# ESP32-H21 register map
Vendor: ESPRESSIF SYSTEMS (SHANGHAI) CO., LTD.; Series: ESP32 H-Series; File version: 1
CPU: RV32IMAC r0p0, little endian, no MPU, no FPU, 0 interrupt priority bits
Address unit: 32 bits
Registers are 32-bit, read-write, reset 0x0 unless marked. A register's access mark holds for its fields unless they carry their own. Offsets are from the block's base; [hi:lo] are bit positions; {n}, {i} and the like mark numbered series.

## EFUSE — eFuse Controller
Base 0x600B4000
{0x0+4i} PGM_DATA{i} (i=0..7) — Represents pgm_data{i}
  [31:0] PGM_DATA — Configures the %sth 32-bit data to be programmed.
{0x20+4i} PGM_CHECK_VALUE{i} (i=0..2) — Represents pgm_check_value{i}
  [31:0] PGM_RS_DATA — Configures the %sth RS code to be programmed.
0x2C RD_WR_DIS ro — Represents rd_wr_dis
  [31:0] WR_DIS — Represents whether programming of individual eFuse memory bit is disabled or enabled.\\ 1: Disabled\\ 0: Enabled\\
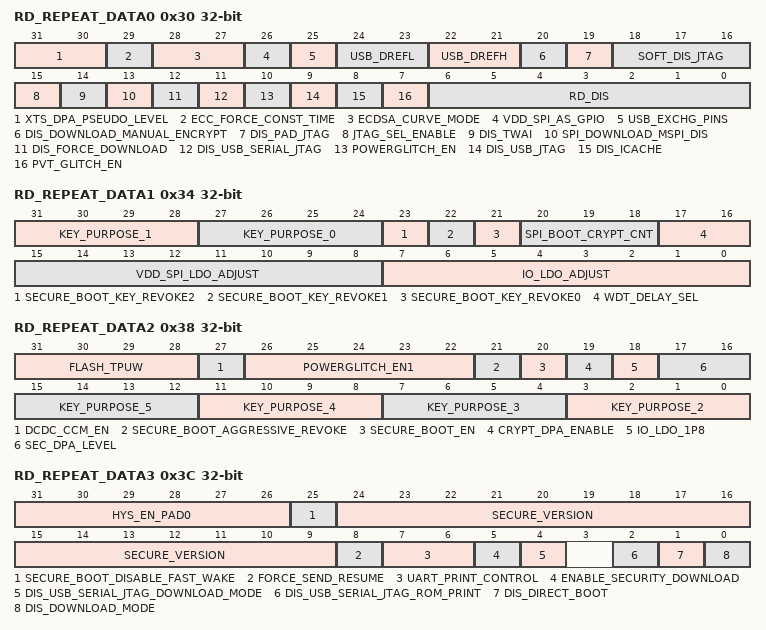
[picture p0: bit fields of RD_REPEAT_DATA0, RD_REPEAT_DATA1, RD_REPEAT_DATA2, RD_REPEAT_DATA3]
0x30 RD_REPEAT_DATA0 ro — Represents rd_repeat_data
  [31:30] XTS_DPA_PSEUDO_LEVEL — Represents control method of xts pseudo-round anti-dpa attack function.\\ 0: Controlled by register\\ 1-3: The higher the value is, the more pseudo-rounds are inserted to the xts-aes calculation.\\
  [29] ECC_FORCE_CONST_TIME — Represents whether to permanently turn on ECC const-time mode.\\ 0: Disabled\\ 1: Enabled\\
  [28:27] ECDSA_CURVE_MODE — Represents the configuration of the curve of ECDSA calculation.\\ 0: Only enable P256\\ 1: Only enable P192\\ 2: Both enable P256 and P192\\ 3: Only enable P256\\
  [26] VDD_SPI_AS_GPIO — Represents whether vdd spi pin is functioned as gpio.\\ 1: Functioned\\ 0: Not functioned\\
  [25] USB_EXCHG_PINS — Represents whether the D+ and D- pins is exchanged.\\ 1: Exchanged\\ 0: Not exchanged\\
  [24:23] USB_DREFL — Represents single-end input threshold vrefl, 0.8 V to 1.04 V with step of 80 mV, stored in eFuse.\\
  [22:21] USB_DREFH — Represents single-end input threshold vrefh, 1.76 V to 2 V with step of 80 mV, stored in eFuse.\\
  [20] DIS_DOWNLOAD_MANUAL_ENCRYPT — Represents whether flash encryption is disabled (except in SPI boot mode).\\ 1: Disabled\\ 0: Enabled\\
  [19] DIS_PAD_JTAG — Represents whether PAD JTAG is disabled in the hard way (permanently).\\ 1: Disabled\\ 0: Enabled\\
  [18:16] SOFT_DIS_JTAG — Represents whether PAD JTAG is disabled in the soft way. It can be restarted via HMAC. \\ Odd count of bits with a value of 1: Disabled\\ Even count of bits with a value of 1: Enabled\\
  [15] JTAG_SEL_ENABLE — Represents whether the selection of a JTAG signal source through the strapping pin value is enabled when both EFUSE_DIS_PAD_JTAG and EFUSE_DIS_USB_JTAG are configured to 0. For more information, please refer to Chapter Placeholder.\\ 1: Enabled\\ 0: Disabled\\
  [14] DIS_TWAI — Represents whether TWAI function is disabled. \\ 1: Disabled\\ 0: Enabled\\
  [13] SPI_DOWNLOAD_MSPI_DIS — Represents accessing MSPI flash/MSPI RAM by SYS AXI matrix is disabled during boot_mode_download.\\ 1: Disabled\\ 0: Enabled\\
  [12] DIS_FORCE_DOWNLOAD — Represents whether the function that forces chip into Download mode is disabled. \\ 1: Disabled\\ 0: Enabled\\
  [11] DIS_USB_SERIAL_JTAG — Represents whether to disable USB-Serial-JTAG.\\
  [10] POWERGLITCH_EN — Represents whether to enable power glitch function.\\
  [9] DIS_USB_JTAG — Represents whether the USB-to-JTAG function in USB Serial/JTAG is disabled. \\ 1: Disabled\\ 0: Enabled\\
  [8] DIS_ICACHE — Represents whether icache is disabled or enabled.\\ 1: Disabled\\ 0: Enabled\\
  [7] PVT_GLITCH_EN — Represents whether to enable PVT power glitch monitor function.\\1: Enable. \\0: Disable\\
  [6:0] RD_DIS — Represents whether reading of individual eFuse block(block4~block10) is disabled or enabled.\\ 1: Disabled\\ 0: Enabled\\
0x34 RD_REPEAT_DATA1 ro — Represents rd_repeat_data
  [31:28] KEY_PURPOSE_1 — Represents the purpose of Key1. See Table tab:efuse-key-purpose.\\
  [27:24] KEY_PURPOSE_0 — Represents the purpose of Key0. See Table tab:efuse-key-purpose.\\
  [23] SECURE_BOOT_KEY_REVOKE2 — Represents whether revoking Secure Boot key 2 is enabled. \\ 1: Enabled\\ 0: Disabled\\
  [22] SECURE_BOOT_KEY_REVOKE1 — Represents whether revoking Secure Boot key 1 is enabled. \\ 1: Enabled\\ 0: Disabled\\
  [21] SECURE_BOOT_KEY_REVOKE0 — Represents whether revoking Secure Boot key 0 is enabled. \\ 1: Enabled\\ 0: Disabled\\
  [20:18] SPI_BOOT_CRYPT_CNT — Represents whether SPI boot encryption/decryption is enabled. \\ Odd count of bits with a value of 1: Enabled\\ Even count of bits with a value of 1: Disabled\\
  [17:16] WDT_DELAY_SEL — Represents RTC watchdog timeout threshold.\\ 0：The originally configured STG0 threshold × 2\\ 1：The originally configured STG0 threshold × 4\\ 2：The originally configured STG0 threshold × 8\\ 3：The originally configured STG0 threshold × 16\\
  [15:8] VDD_SPI_LDO_ADJUST — Represents configuration of FLASH LDO mode and voltage.\\
  [7:0] IO_LDO_ADJUST — Represents configuration of IO LDO mode and voltage.\\
0x38 RD_REPEAT_DATA2 ro — Represents rd_repeat_data
  [31:28] FLASH_TPUW — Represents the flash waiting time after power-up. Measurement unit: ms.\\ When the value is less than 15, the waiting time is the programmed value. Otherwise, the waiting time is a fixed value, i.e. 30 ms.\\
  [27] DCDC_CCM_EN — Represents whether change DCDC to CCM mode.
  [26:22] POWERGLITCH_EN1 — Represents whether to enable power glitch function when chip power on.\\
  [21] SECURE_BOOT_AGGRESSIVE_REVOKE — Represents whether aggressive revocation of Secure Boot is enabled.\\ 1: Enabled\\ 0: Disabled\\
  [20] SECURE_BOOT_EN — Represents whether Secure Boot is enabled.\\ 1: Enabled\\ 0: Disabled\\
  [19] CRYPT_DPA_ENABLE — Represents whether defense against DPA attack is enabled.\\ 1: Enabled\\ 0: Disabled\\
  [18] IO_LDO_1P8 — Represents select IO LDO voltage to 1.8V or 3.3V.\\ 1: 1.8V\\ 0: 3.3V\\
  [17:16] SEC_DPA_LEVEL — Represents the security level of anti-DPA attack. The level is adjusted by configuring the clock random frequency division mode.\\ 0: Security level is SEC_DPA_OFF\\ 1: Security level is SEC_DPA_LOW\\ 2: Security level is SEC_DPA_MIDDLE\\ 3: Security level is SEC_DPA_HIGH\\ For more information, please refer to Chapter mod:sysreg > Section sec:sysreg-anti-dpa-attack-security-control.\\
  [4n-5:4n-8] KEY_PURPOSE_{n} (n=2..5) — Represents the purpose of Key{n}. See Table tab:efuse-key-purpose.\\
0x3C RD_REPEAT_DATA3 ro — Represents rd_repeat_data
  [31:26] HYS_EN_PAD0 — Represents whether to enable the hysteresis function of pad 0-5.\\ 0: Disabled\\ 1: Enabled\\
  [25] SECURE_BOOT_DISABLE_FAST_WAKE — Represents whether FAST VERIFY ON WAKE is disabled when Secure Boot is enabled.\\ 1: Disabled\\ 0: Enabled\\
  [24:9] SECURE_VERSION — Represents the security version used by ESP-IDF anti-rollback feature.\\
  [8] FORCE_SEND_RESUME — Represents whether ROM code is forced to send a resume command during SPI boot.\\ 1: Forced\\ 0: Not forced\\
  [7:6] UART_PRINT_CONTROL — Represents the type of UART printing.\\ 0: Force enable printing.\\ 1: Enable printing when GPIO8 is reset at low level.\\ 2: Enable printing when GPIO8 is reset at high level.\\ 3: Force disable printing.\\
  [5] ENABLE_SECURITY_DOWNLOAD — Represents whether security download is enabled. Only UART is supported for download. Reading/writing RAM or registers is not supported (i.e. Stub download is not supported).\\ 1: Enabled\\ 0: Disabled\\
  [4] DIS_USB_SERIAL_JTAG_DOWNLOAD_MODE — Represents whether the USB-Serial-JTAG download function is disabled.\\ 1: Disabled\\ 0: Enabled\\
  [2] DIS_USB_SERIAL_JTAG_ROM_PRINT — Represents whether print from USB-Serial-JTAG during ROM boot is disabled.\\ 1: Disabled\\ 0: Enabled\\
  [1] DIS_DIRECT_BOOT — Represents whether direct boot mode is disabled.\\ 1: Disabled\\ 0: Enabled\\
  [0] DIS_DOWNLOAD_MODE — Represents whether all download modes are disabled.\\ 1: Disabled\\ 0: Enabled\\
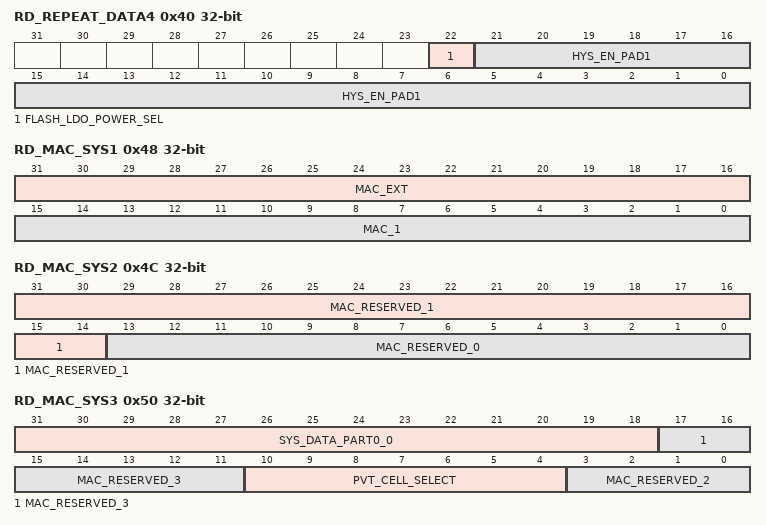
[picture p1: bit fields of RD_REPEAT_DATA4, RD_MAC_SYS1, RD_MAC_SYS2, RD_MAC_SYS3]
0x40 RD_REPEAT_DATA4 ro — Represents rd_repeat_data
  [22] FLASH_LDO_POWER_SEL — Represents which flash LDO is selected.\\ 0: FLASH LDO 1P8.\\ 1: FLASH LDO 1P2.\\
  [21:0] HYS_EN_PAD1 — Represents whether to enable the hysteresis function of pad 6-27.\\ 0: Disabled\\ 1: Enabled\\
0x44 RD_MAC_SYS0 ro — Represents rd_mac_sys
  [31:0] MAC_0 — Represents MAC address. Low 32-bit.
0x48 RD_MAC_SYS1 ro — Represents rd_mac_sys
  [31:16] MAC_EXT — Represents the extended bits of MAC address.
  [15:0] MAC_1 — Represents MAC address. High 16-bit.
0x4C RD_MAC_SYS2 ro — Represents rd_mac_sys
  [31:14] MAC_RESERVED_1 — Reserved.
  [13:0] MAC_RESERVED_0 — Reserved.
0x50 RD_MAC_SYS3 ro — Represents rd_mac_sys
  [31:18] SYS_DATA_PART0_0 — Represents the first 14-bit of zeroth part of system data.
  [17:11] MAC_RESERVED_3 — Reserved.
  [10:4] PVT_CELL_SELECT — Represents the selection of Power glitch monitor PVT cell.\\
  [3:0] MAC_RESERVED_2 — Reserved.
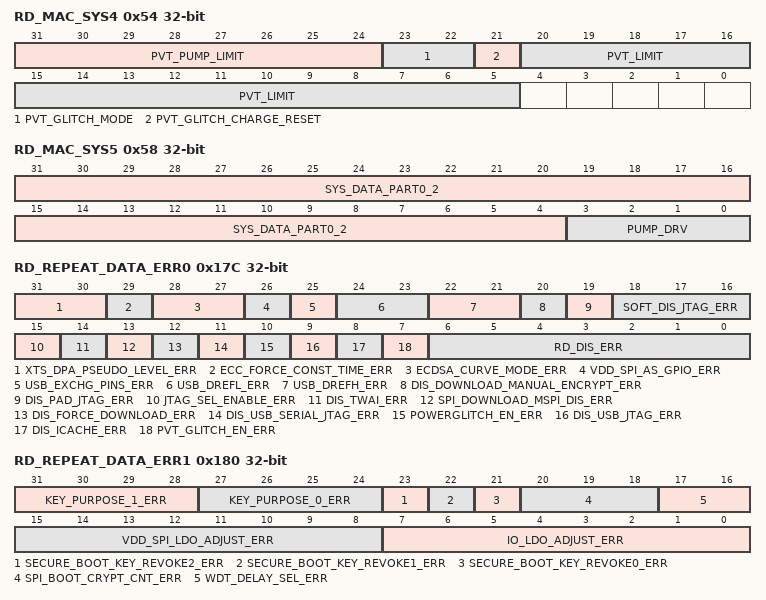
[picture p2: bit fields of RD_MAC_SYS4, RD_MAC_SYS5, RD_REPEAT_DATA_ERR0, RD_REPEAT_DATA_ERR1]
0x54 RD_MAC_SYS4 ro — Represents rd_mac_sys
  [31:24] PVT_PUMP_LIMIT — Represents the configuration voltage monitor limit for charge pump.\\
  [23:22] PVT_GLITCH_MODE — Represents the configuration of glitch mode.\\
  [21] PVT_GLITCH_CHARGE_RESET — Represents whether to trigger reset or charge pump when PVT power glitch happened.\\ 1:Trigger charge pump. \\ 0:Trigger reset\\
  [20:5] PVT_LIMIT — Represents the threshold of power glitch monitor.\\
0x58 RD_MAC_SYS5 ro — Represents rd_mac_sys
  [31:4] SYS_DATA_PART0_2 — Represents the second 28-bit of zeroth part of system data.
  [3:0] PUMP_DRV — Use to configure charge pump voltage gain.\\
{0x5C+4i} RD_SYS_PART1_DATA{i} (i=0..7) ro — Represents rd_sys_part1_data{i}
  [31:0] SYS_DATA_PART1 — Represents the zeroth 32-bit of first part of system data.
{0x7C+4i} RD_USR_DATA{i} (i=0..7) ro — Represents rd_usr_data{i}
  [31:0] USR_DATA — Represents the zeroth 32-bit of block3 (user).
{0x9C+4i} RD_KEY0_DATA{i} (i=0..7) ro — Represents rd_key0_data{i}
  [31:0] KEY0_DATA — Represents the zeroth 32-bit of key0.
{0xBC+4i} RD_KEY1_DATA{i} (i=0..7) ro — Represents rd_key1_data{i}
  [31:0] KEY1_DATA — Represents the zeroth 32-bit of key1.
{0xDC+4i} RD_KEY2_DATA{i} (i=0..7) ro — Represents rd_key2_data{i}
  [31:0] KEY2_DATA — Represents the zeroth 32-bit of key2.
{0xFC+4i} RD_KEY3_DATA{i} (i=0..7) ro — Represents rd_key3_data{i}
  [31:0] KEY3_DATA — Represents the zeroth 32-bit of key3.
{0x11C+4i} RD_KEY4_DATA{i} (i=0..7) ro — Represents rd_key4_data{i}
  [31:0] KEY4_DATA — Represents the zeroth 32-bit of key4.
{0x13C+4i} RD_KEY5_DATA{i} (i=0..7) ro — Represents rd_key5_data{i}
  [31:0] KEY5_DATA — Represents the zeroth 32-bit of key5.
{0x15C+4i} RD_SYS_PART2_DATA{i} (i=0..7) ro — Represents rd_sys_part2_data{i}
  [31:0] SYS_DATA_PART2 — Represents the zeroth 32-bit of second part of system data.
0x17C RD_REPEAT_DATA_ERR0 ro — Represents rd_repeat_data_err
  [31:30] XTS_DPA_PSEUDO_LEVEL_ERR — Represents the programming error of EFUSE_XTS_DPA_PSEUDO_LEVEL
  [29] ECC_FORCE_CONST_TIME_ERR — Represents the programming error of EFUSE_ECC_FORCE_CONST_TIME
  [28:27] ECDSA_CURVE_MODE_ERR — Represents the programming error of EFUSE_ECDSA_CURVE_MODE
  [26] VDD_SPI_AS_GPIO_ERR — Represents the programming error of EFUSE_VDD_SPI_AS_GPIO
  [25] USB_EXCHG_PINS_ERR — Represents the programming error of EFUSE_USB_EXCHG_PINS
  [24:23] USB_DREFL_ERR — Represents the programming error of EFUSE_USB_DREFL
  [22:21] USB_DREFH_ERR — Represents the programming error of EFUSE_USB_DREFH
  [20] DIS_DOWNLOAD_MANUAL_ENCRYPT_ERR — Represents the programming error of EFUSE_DIS_DOWNLOAD_MANUAL_ENCRYPT
  [19] DIS_PAD_JTAG_ERR — Represents the programming error of EFUSE_DIS_PAD_JTAG
  [18:16] SOFT_DIS_JTAG_ERR — Represents the programming error of EFUSE_SOFT_DIS_JTAG
  [15] JTAG_SEL_ENABLE_ERR — Represents the programming error of EFUSE_JTAG_SEL_ENABLE
  [14] DIS_TWAI_ERR — Represents the programming error of EFUSE_DIS_TWAI
  [13] SPI_DOWNLOAD_MSPI_DIS_ERR — Represents the programming error of EFUSE_SPI_DOWNLOAD_MSPI_DIS
  [12] DIS_FORCE_DOWNLOAD_ERR — Represents the programming error of EFUSE_DIS_FORCE_DOWNLOAD
  [11] DIS_USB_SERIAL_JTAG_ERR — Represents the programming error of EFUSE_DIS_USB_SERIAL_JTAG
  [10] POWERGLITCH_EN_ERR — Represents the programming error of EFUSE_POWERGLITCH_EN
  [9] DIS_USB_JTAG_ERR — Represents the programming error of EFUSE_DIS_USB_JTAG
  [8] DIS_ICACHE_ERR — Represents the programming error of EFUSE_DIS_ICACHE
  [7] PVT_GLITCH_EN_ERR — Represents the programming error of EFUSE_PVT_GLITCH_EN
  [6:0] RD_DIS_ERR — Represents the programming error of EFUSE_RD_DIS
0x180 RD_REPEAT_DATA_ERR1 ro — Represents rd_repeat_data_err
  [31:28] KEY_PURPOSE_1_ERR — Represents the programming error of EFUSE_KEY_PURPOSE_1
  [27:24] KEY_PURPOSE_0_ERR — Represents the programming error of EFUSE_KEY_PURPOSE_0
  [23] SECURE_BOOT_KEY_REVOKE2_ERR — Represents the programming error of EFUSE_SECURE_BOOT_KEY_REVOKE2
  [22] SECURE_BOOT_KEY_REVOKE1_ERR — Represents the programming error of EFUSE_SECURE_BOOT_KEY_REVOKE1
  [21] SECURE_BOOT_KEY_REVOKE0_ERR — Represents the programming error of EFUSE_SECURE_BOOT_KEY_REVOKE0
  [20:18] SPI_BOOT_CRYPT_CNT_ERR — Represents the programming error of EFUSE_SPI_BOOT_CRYPT_CNT
  [17:16] WDT_DELAY_SEL_ERR — Represents the programming error of EFUSE_WDT_DELAY_SEL
  [15:8] VDD_SPI_LDO_ADJUST_ERR — Represents the programming error of EFUSE_VDD_SPI_LDO_ADJUST
  [7:0] IO_LDO_ADJUST_ERR — Represents the programming error of EFUSE_IO_LDO_ADJUST
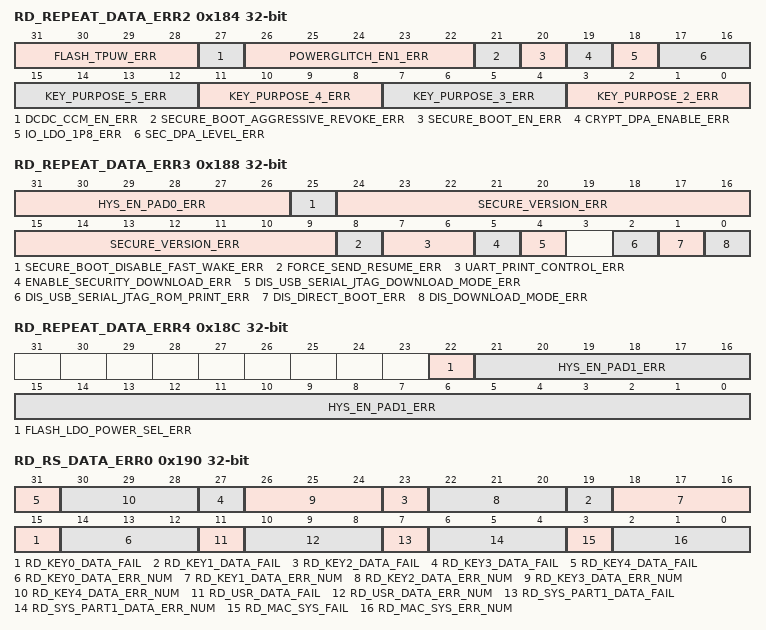
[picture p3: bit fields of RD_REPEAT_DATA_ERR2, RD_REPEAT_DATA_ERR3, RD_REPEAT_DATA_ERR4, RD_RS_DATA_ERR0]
0x184 RD_REPEAT_DATA_ERR2 ro — Represents rd_repeat_data_err
  [31:28] FLASH_TPUW_ERR — Represents the programming error of EFUSE_FLASH_TPUW
  [27] DCDC_CCM_EN_ERR — Represents the programming error of EFUSE_DCDC_CCM_EN
  [26:22] POWERGLITCH_EN1_ERR — Represents the programming error of EFUSE_POWERGLITCH_EN1
  [21] SECURE_BOOT_AGGRESSIVE_REVOKE_ERR — Represents the programming error of EFUSE_SECURE_BOOT_AGGRESSIVE_REVOKE
  [20] SECURE_BOOT_EN_ERR — Represents the programming error of EFUSE_SECURE_BOOT_EN
  [19] CRYPT_DPA_ENABLE_ERR — Represents the programming error of EFUSE_CRYPT_DPA_ENABLE
  [18] IO_LDO_1P8_ERR — Represents the programming error of EFUSE_IO_LDO_1P8
  [17:16] SEC_DPA_LEVEL_ERR — Represents the programming error of EFUSE_SEC_DPA_LEVEL
  [4n-5:4n-8] KEY_PURPOSE_{n}_ERR (n=2..5) — Represents the programming error of EFUSE_KEY_PURPOSE_{n}
0x188 RD_REPEAT_DATA_ERR3 ro — Represents rd_repeat_data_err
  [31:26] HYS_EN_PAD0_ERR — Represents the programming error of EFUSE_HYS_EN_PAD0
  [25] SECURE_BOOT_DISABLE_FAST_WAKE_ERR — Represents the programming error of EFUSE_SECURE_BOOT_DISABLE_FAST_WAKE
  [24:9] SECURE_VERSION_ERR — Represents the programming error of EFUSE_SECURE_VERSION
  [8] FORCE_SEND_RESUME_ERR — Represents the programming error of EFUSE_FORCE_SEND_RESUME
  [7:6] UART_PRINT_CONTROL_ERR — Represents the programming error of EFUSE_UART_PRINT_CONTROL
  [5] ENABLE_SECURITY_DOWNLOAD_ERR — Represents the programming error of EFUSE_ENABLE_SECURITY_DOWNLOAD
  [4] DIS_USB_SERIAL_JTAG_DOWNLOAD_MODE_ERR — Represents the programming error of EFUSE_DIS_USB_SERIAL_JTAG_DOWNLOAD_MODE
  [2] DIS_USB_SERIAL_JTAG_ROM_PRINT_ERR — Represents the programming error of EFUSE_DIS_USB_SERIAL_JTAG_ROM_PRINT
  [1] DIS_DIRECT_BOOT_ERR — Represents the programming error of EFUSE_DIS_DIRECT_BOOT
  [0] DIS_DOWNLOAD_MODE_ERR — Represents the programming error of EFUSE_DIS_DOWNLOAD_MODE
0x18C RD_REPEAT_DATA_ERR4 ro — Represents rd_repeat_data_err
  [22] FLASH_LDO_POWER_SEL_ERR — Represents the programming error of EFUSE_FLASH_LDO_POWER_SEL
  [21:0] HYS_EN_PAD1_ERR — Represents the programming error of EFUSE_HYS_EN_PAD1
0x190 RD_RS_DATA_ERR0 ro — Represents rd_rs_data_err
  [4n+15] RD_KEY{n}_DATA_FAIL (n=0..4) — Represents error status of register.\\0: Means no failure and that the data of rd_key{n}_data is reliable\\ 1: Means that programming rd_key{n}_data failed and the number of error bytes is over 6.
  [4n+14:4n+12] RD_KEY{n}_DATA_ERR_NUM (n=0..4) — Represents the error number of registers.\\The value of this signal means the number of error bytes in rd_key{n}_data
  [11] RD_USR_DATA_FAIL — Represents error status of register.\\0: Means no failure and that the data of rd_usr_data is reliable\\ 1: Means that programming rd_usr_data failed and the number of error bytes is over 6.
  [10:8] RD_USR_DATA_ERR_NUM — Represents the error number of registers.\\The value of this signal means the number of error bytes in rd_usr_data
  [7] RD_SYS_PART1_DATA_FAIL — Represents error status of register.\\0: Means no failure and that the data of rd_sys_part1_data is reliable\\ 1: Means that programming rd_sys_part1_data failed and the number of error bytes is over 6.
  [6:4] RD_SYS_PART1_DATA_ERR_NUM — Represents the error number of registers.\\The value of this signal means the number of error bytes in rd_sys_part1_data
  [3] RD_MAC_SYS_FAIL — Represents error status of register.\\0: Means no failure and that the data of rd_mac_sys is reliable\\ 1: Means that programming rd_mac_sys failed and the number of error bytes is over 6.
  [2:0] RD_MAC_SYS_ERR_NUM — Represents the error number of registers.\\The value of this signal means the number of error bytes in rd_mac_sys
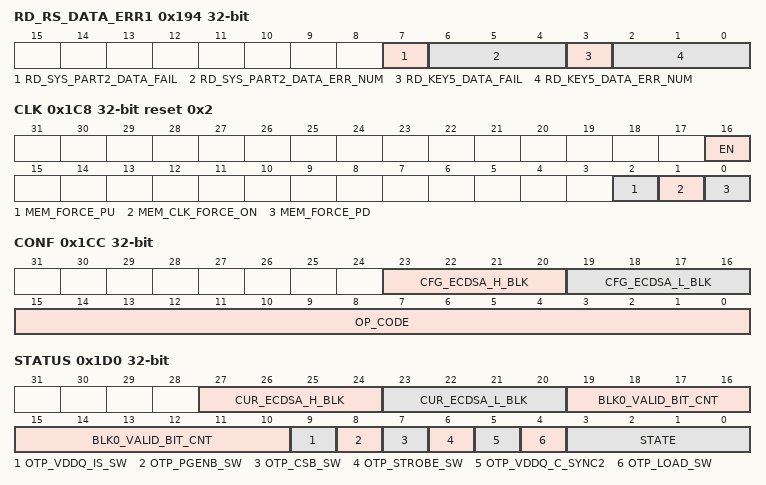
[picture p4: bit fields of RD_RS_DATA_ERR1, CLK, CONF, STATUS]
0x194 RD_RS_DATA_ERR1 ro — Represents rd_rs_data_err
  [7] RD_SYS_PART2_DATA_FAIL — Represents error status of register.\\0: Means no failure and that the data of rd_sys_part2_data is reliable\\ 1: Means that programming rd_sys_part2_data failed and the number of error bytes is over 6.
  [6:4] RD_SYS_PART2_DATA_ERR_NUM — Represents the error number of registers.\\The value of this signal means the number of error bytes in rd_sys_part2_data
  [3] RD_KEY5_DATA_FAIL — Represents error status of register.\\0: Means no failure and that the data of rd_key5_data is reliable\\ 1: Means that programming rd_key5_data failed and the number of error bytes is over 6.
  [2:0] RD_KEY5_DATA_ERR_NUM — Represents the error number of registers.\\The value of this signal means the number of error bytes in rd_key5_data
0x198 DATE reset 0x2410120 — eFuse version register.
  [27:0] DATE — Represents eFuse version. Date:2024-10-12 12:09:57, ScriptRev:892332a1019d3a17987b08c6835edce28f46e261
0x1C8 CLK reset 0x2 — eFuse clcok configuration register.
  [16] EN — Configures whether to force enable eFuse register configuration clock signal.\\ 1: Force\\ 0: The clock is enabled only during the reading and writing of registers\\
  [2] MEM_FORCE_PU — Configures whether to force power up eFuse SRAM.\\ 1: Force\\ 0: No effect\\
  [1] MEM_CLK_FORCE_ON — Configures whether to force activate clock signal of eFuse SRAM.\\ 1: Force activate\\ 0: No effect\\
  [0] MEM_FORCE_PD — Configures whether to force power down eFuse SRAM.\\ 1: Force\\ 0: No effect\\
0x1CC CONF — eFuse operation mode configuraiton register
  [23:20] CFG_ECDSA_H_BLK — Configures which block to use for ECDSA key high part output.
  [19:16] CFG_ECDSA_L_BLK — Configures which block to use for ECDSA key low part output.
  [15:0] OP_CODE — Configures operation command type.\\ 0x5A5A: Program operation command\\ 0x5AA5: Read operation command\\ Other values: No effect\\
0x1D0 STATUS ro — eFuse status register.
  [27:24] CUR_ECDSA_H_BLK — Represents which block is used for ECDSA key high part output.
  [23:20] CUR_ECDSA_L_BLK — Represents which block is used for ECDSA key low part output.
  [19:10] BLK0_VALID_BIT_CNT — Represents the number of block valid bit.
  [9] OTP_VDDQ_IS_SW — Represents the value of OTP_VDDQ_IS_SW.
  [8] OTP_PGENB_SW — Represents the value of OTP_PGENB_SW.
  [7] OTP_CSB_SW — Represents the value of OTP_CSB_SW.
  [6] OTP_STROBE_SW — Represents the value of OTP_STROBE_SW.
  [5] OTP_VDDQ_C_SYNC2 — Represents the value of OTP_VDDQ_C_SYNC2.
  [4] OTP_LOAD_SW — Represents the value of OTP_LOAD_SW.
  [3:0] STATE — Represents the state of the eFuse state machine.\\ 0: Reset state, the initial state after power-up\\ 1: Idle state\\ Other values: Non-idle state\\
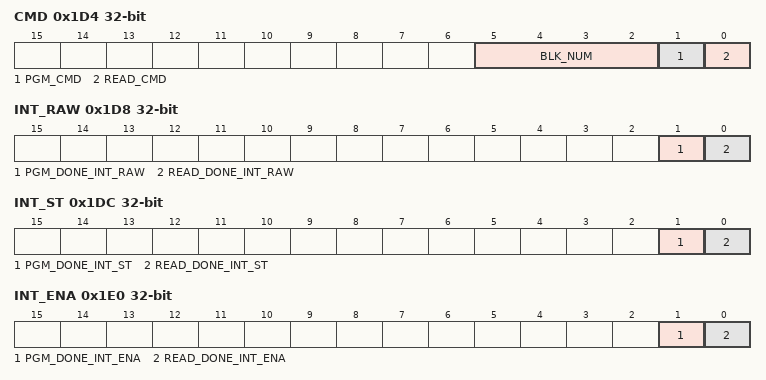
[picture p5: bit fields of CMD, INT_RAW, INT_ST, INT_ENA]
0x1D4 CMD — eFuse command register.
  [5:2] BLK_NUM — Configures the serial number of the block to be programmed. Value 0-10 corresponds to block number 0-10, respectively.
  [1] PGM_CMD — Configures whether to send programing commands.\\ 1: Send\\ 0: No effect\\
  [0] READ_CMD — Configures whether to send read commands.\\ 1: Send\\ 0: No effect\\
0x1D8 INT_RAW ro — eFuse raw interrupt register.
  [1] PGM_DONE_INT_RAW — The raw interrupt status of EFUSE_PGM_DONE_INT.
  [0] READ_DONE_INT_RAW — The raw interrupt status of EFUSE_READ_DONE_INT.
0x1DC INT_ST ro — eFuse interrupt status register.
  [1] PGM_DONE_INT_ST — The masked interrupt status of EFUSE_PGM_DONE_INT.
  [0] READ_DONE_INT_ST — The masked interrupt status of EFUSE_READ_DONE_INT.
0x1E0 INT_ENA — eFuse interrupt enable register.
  [1] PGM_DONE_INT_ENA — Write 1 to enable EFUSE_PGM_DONE_INT.
  [0] READ_DONE_INT_ENA — Write 1 to enable EFUSE_READ_DONE_INT.
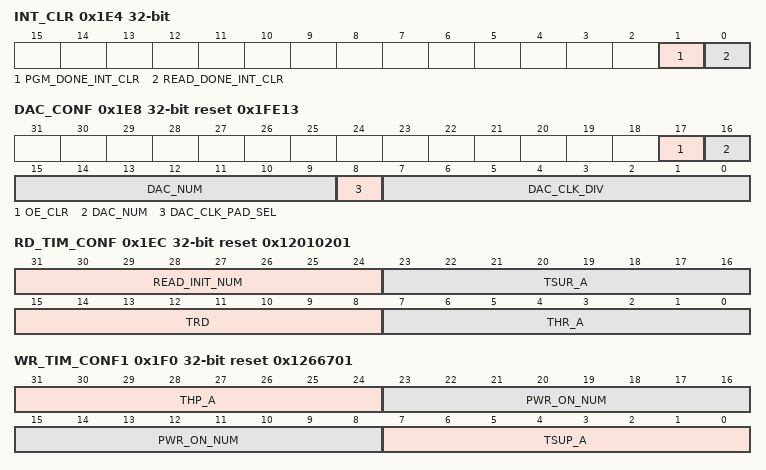
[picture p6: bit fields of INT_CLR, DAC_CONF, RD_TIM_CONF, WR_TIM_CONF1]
0x1E4 INT_CLR wo — eFuse interrupt clear register.
  [1] PGM_DONE_INT_CLR — Write 1 to clear EFUSE_PGM_DONE_INT.
  [0] READ_DONE_INT_CLR — Write 1 to clear EFUSE_READ_DONE_INT.
0x1E8 DAC_CONF reset 0x1FE13 — Controls the eFuse programming voltage.
  [17] OE_CLR — Configures whether to reduce the power supply of programming voltage.\\ 0: Not reduce\\ 1: Reduce\\
  [16:9] DAC_NUM — Configures clock cycles for programming voltage to rise. Measurement unit: a clock cycle divided by EFUSE_DAC_CLK_DIV.
  [8] DAC_CLK_PAD_SEL — Don't care.
  [7:0] DAC_CLK_DIV — Configures the division factor of the rising clock of the programming voltage.
0x1EC RD_TIM_CONF reset 0x12010201 — Configures read timing parameters.
  [31:24] READ_INIT_NUM — Configures the waiting time of reading eFuse memory. Measurement unit: One cycle of the eFuse core clock.
  [23:16] TSUR_A — Configures the read setup time. Measurement unit: One cycle of the eFuse core clock.
  [15:8] TRD — Configures the read time. Measurement unit: One cycle of the eFuse core clock.
  [7:0] THR_A — Configures the read hold time. Measurement unit: One cycle of the eFuse core clock.
0x1F0 WR_TIM_CONF1 reset 0x1266701 — Configurarion register 1 of eFuse programming timing parameters.
  [31:24] THP_A — Configures the programming hold time. Measurement unit: One cycle of the eFuse core clock.
  [23:8] PWR_ON_NUM — Configures the power up time for VDDQ. Measurement unit: One cycle of the eFuse core clock.
  [7:0] TSUP_A — Configures the programming setup time. Measurement unit: One cycle of the eFuse core clock.
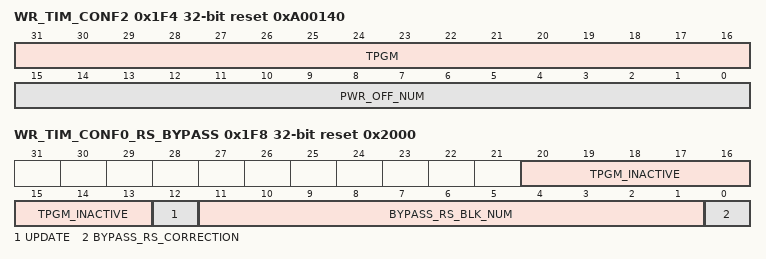
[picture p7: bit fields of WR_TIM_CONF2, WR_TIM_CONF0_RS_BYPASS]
0x1F4 WR_TIM_CONF2 reset 0xA00140 — Configurarion register 2 of eFuse programming timing parameters.
  [31:16] TPGM — Configures the active programming time. Measurement unit: One cycle of the eFuse core clock.
  [15:0] PWR_OFF_NUM — Configures the power outage time for VDDQ. Measurement unit: One cycle of the eFuse core clock.
0x1F8 WR_TIM_CONF0_RS_BYPASS access per field reset 0x2000 — Configurarion register0 of eFuse programming time parameters and rs bypass operation.
  [20:13] TPGM_INACTIVE rw — Configures the inactive programming time. Measurement unit: One cycle of the eFuse core clock.
  [12] UPDATE wo — Configures whether to update multi-bit register signals.\\ 1: Update\\ 0: No effect\\
  [11:1] BYPASS_RS_BLK_NUM rw — Configures which block number to bypass the Reed-Solomon (RS) correction step.
  [0] BYPASS_RS_CORRECTION rw — Configures whether to bypass the Reed-Solomon (RS) correction step.\\ 0: Not bypass\\ 1: Bypass\\
0x500 APB2OTP_WR_DIS ro — eFuse apb2otp block0 data register1.
  [31:0] APB2OTP_BLOCK0_WR_DIS — Otp block0 write disable data.
{0x500+4i} APB2OTP_BLK0_BACKUP1_W{i} ro (i=1..5) — eFuse apb2otp block0 data register{i+1}.
  [31:0] APB2OTP_BLOCK0_BACKUP1_W{i} — Otp block0 backup1 word{i} data.
{0x514+4i} APB2OTP_BLK0_BACKUP2_W{i} ro (i=1..5) — eFuse apb2otp block0 data register{i+6}.
  [31:0] APB2OTP_BLOCK0_BACKUP2_W{i} — Otp block0 backup2 word{i} data.
{0x528+4i} APB2OTP_BLK0_BACKUP3_W{i} ro (i=1..5) — eFuse apb2otp block0 data register{i+11}.
  [31:0] APB2OTP_BLOCK0_BACKUP3_W{i} — Otp block0 backup3 word{i} data.
{0x53C+4i} APB2OTP_BLK0_BACKUP4_W{i} ro (i=1..5) — eFuse apb2otp block0 data register{i+16}.
  [31:0] APB2OTP_BLOCK0_BACKUP4_W{i} — Otp block0 backup4 word{i} data.
{0x550+4i} APB2OTP_BLK1_W{i} ro (i=1..9) — eFuse apb2otp block1 data register{i}.
  [31:0] APB2OTP_BLOCK1_W{i} — Otp block1 word{i} data.
{0x574+4i} APB2OTP_BLK2_W{i} ro (i=1..11) — eFuse apb2otp block2 data register{i}.
  [31:0] APB2OTP_BLOCK2_W{i} — Otp block2 word{i} data.
{0x5A0+4i} APB2OTP_BLK3_W{i} ro (i=1..11) — eFuse apb2otp block3 data register{i}.
  [31:0] APB2OTP_BLOCK3_W{i} — Otp block3 word{i} data.
0x5D0 APB2OTP_BLK4_W1 ro — eFuse apb2otp BLOCK7 data register1.
  [31:0] APB2OTP_BLOCK4_W1 — Otp block4 word1 data.
{0x5CC+4i} APB2OTP_BLK4_W{i} ro (i=2..9) — eFuse apb2otp block4 data register{i}.
  [31:0] APB2OTP_BLOCK4_W{i} — Otp block4 word{i} data.
0x5F4 APB2OTP_BLK4_W10 ro — eFuse apb2otp block4 data registe10.
  [31:0] APB2OTP_BLOCK4_W10 — Otp block4 word10 data.
0x5F8 APB2OTP_BLK4_W11 ro — eFuse apb2otp block4 data register11.
  [31:0] APB2OTP_BLOCK4_W11 — Otp block4 word11 data.
{0x5F8+4i} APB2OTP_BLK5_W{i} ro (i=1..11) — eFuse apb2otp block5 data register{i}.
  [31:0] APB2OTP_BLOCK5_W{i} — Otp block5 word{i} data.
{0x624+4i} APB2OTP_BLK6_W{i} ro (i=1..11) — eFuse apb2otp block6 data register{i}.
  [31:0] APB2OTP_BLOCK6_W{i} — Otp block6 word{i} data.
{0x650+4i} APB2OTP_BLK7_W{i} ro (i=1..11) — eFuse apb2otp block7 data register{i}.
  [31:0] APB2OTP_BLOCK7_W{i} — Otp block7 word{i} data.
{0x67C+4i} APB2OTP_BLK8_W{i} ro (i=1..11) — eFuse apb2otp block8 data register{i}.
  [31:0] APB2OTP_BLOCK8_W{i} — Otp block8 word{i} data.
{0x6A8+4i} APB2OTP_BLK9_W{i} ro (i=1..11) — eFuse apb2otp block9 data register{i}.
  [31:0] APB2OTP_BLOCK9_W{i} — Otp block9 word{i} data.
{0x6D4+4i} APB2OTP_BLK10_W{i} ro (i=1..11) — eFuse apb2otp block10 data register{i}.
  [31:0] APB2OTP_BLOCK10_W{i} — Otp block10 word{i} data.
0x708 APB2OTP_EN — eFuse apb2otp enable configuration register.
  [0] APB2OTP_APB2OTP_EN — Apb2otp mode enable signal.
